AUTOSAR XML (schema 4-2-2)
package /EB/SoftwareComponents
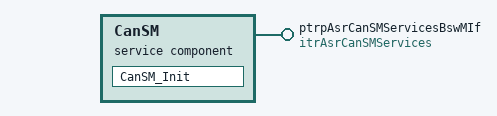
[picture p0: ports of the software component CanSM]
  service sw component type CanSM: category=ASR_Interfaces
    provide port ptrpAsrCanSMServicesBswMIf: provided-interface=itrAsrCanSMServices
    behavior CanSM_IB: handle-termination-and-restart=NO-SUPPORT
      runnable CanSM_Init
package /EB/TriggerInterfaces
  trigger interface itrAsrCanSMServices
    trigger CanSM_Init: trigger-period={cse-code=1000, cse-code-factor=0}
